# can register map
Vendor: Texas Instruments
Peripheral module from a debugger description file (folder sc4cc231e6pm).
Registers are 32-bit, read-write, no defined reset value unless marked. A register's access mark holds for its fields unless they carry their own. Offsets are as the file gives them; lines under a group give offsets from that group; [hi:lo] are bit positions; {n}, {i} and the like mark numbered series; 'fields as' and 'values as' point back to an identical list; <NAME> marks a mode.

## CAN0 — CAN register offsets
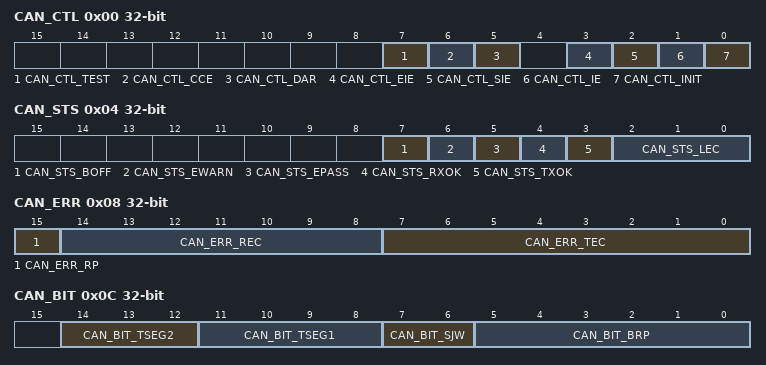
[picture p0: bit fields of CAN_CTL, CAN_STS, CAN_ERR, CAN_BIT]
0x00 CAN_CTL — CAN Control
  [7] CAN_CTL_TEST — Test Mode Enable
  [6] CAN_CTL_CCE — Configuration Change Enable
  [5] CAN_CTL_DAR — Disable Automatic-Retransmission
  [3] CAN_CTL_EIE — Error Interrupt Enable
  [2] CAN_CTL_SIE — Status Interrupt Enable
  [1] CAN_CTL_IE — CAN Interrupt Enable
  [0] CAN_CTL_INIT — Initialization
0x04 CAN_STS — CAN Status
  [7] CAN_STS_BOFF — Bus-Off Status
  [6] CAN_STS_EWARN — Warning Status
  [5] CAN_STS_EPASS — Error Passive
  [4] CAN_STS_RXOK — Received a Message Successfully
  [3] CAN_STS_TXOK — Transmitted a Message Successfully
  [2:0] CAN_STS_LEC — Last Error Code
    0=CAN_STS_LEC_NONE (No Error); 1=CAN_STS_LEC_STUFF (Stuff Error); 2=CAN_STS_LEC_FORM (Format Error); 3=CAN_STS_LEC_ACK (ACK Error); 4=CAN_STS_LEC_BIT1 (Bit 1 Error); 5=CAN_STS_LEC_BIT0 (Bit 0 Error); 6=CAN_STS_LEC_CRC (CRC Error); 7=CAN_STS_LEC_NOEVENT (No Event)
0x08 CAN_ERR ro — CAN Error Counter
  [15] CAN_ERR_RP — Received Error Passive
  [14:8] CAN_ERR_REC — Receive Error Counter
  [7:0] CAN_ERR_TEC — Transmit Error Counter
0x0C CAN_BIT — CAN Bit Timing
  [14:12] CAN_BIT_TSEG2 — Time Segment after Sample Point
  [11:8] CAN_BIT_TSEG1 — Time Segment Before Sample Point
  [7:6] CAN_BIT_SJW — (Re)Synchronization Jump Width
  [5:0] CAN_BIT_BRP — Baud Rate Prescaler
0x10 CAN_INT ro — CAN Interrupt
  [15:0] CAN_INT_INTID — Interrupt Identifier
    0=CAN_INT_INTID_NONE (No interrupt pending); 0x8000=CAN_INT_INTID_STATUS (Status Interrupt)
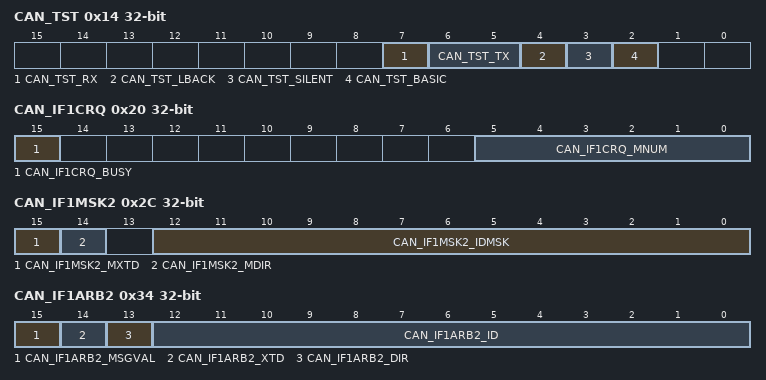
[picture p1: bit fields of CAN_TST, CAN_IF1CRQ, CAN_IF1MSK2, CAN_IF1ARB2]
0x14 CAN_TST — CAN Test
  [7] CAN_TST_RX — Receive Observation
  [6:5] CAN_TST_TX — Transmit Control
    0=CAN_TST_TX_CANCTL (CAN Module Control); 1=CAN_TST_TX_SAMPLE (Sample Point); 2=CAN_TST_TX_DOMINANT (Driven Low); 3=CAN_TST_TX_RECESSIVE (Driven High)
  [4] CAN_TST_LBACK — Loopback Mode
  [3] CAN_TST_SILENT — Silent Mode
  [2] CAN_TST_BASIC — Basic Mode
0x18 CAN_BRPE — CAN Baud Rate Prescaler Extension
  [3:0] CAN_BRPE_BRPE — Baud Rate Prescaler Extension
0x20 CAN_IF1CRQ — CAN IF1 Command Request
  [15] CAN_IF1CRQ_BUSY — Busy Flag
  [5:0] CAN_IF1CRQ_MNUM — Message Number
0x24 CAN_IF1CMSK — CAN IF1 Command Mask
  [7] CAN_IF1CMSK_WRNRD — Write, Not Read
  [6] CAN_IF1CMSK_MASK — Access Mask Bits
  [5] CAN_IF1CMSK_ARB — Access Arbitration Bits
  [4] CAN_IF1CMSK_CONTROL — Access Control Bits
  [3] CAN_IF1CMSK_CLRINTPND — Clear Interrupt Pending Bit
  [2] CAN_IF1CMSK_NEWDAT — Access New Data
  [2] CAN_IF1CMSK_TXRQST — Access Transmission Request
  [1] CAN_IF1CMSK_DATAA — Access Data Byte 0 to 3
  [0] CAN_IF1CMSK_DATAB — Access Data Byte 4 to 7
0x28 CAN_IF1MSK1 — CAN IF1 Mask 1
  [15:0] CAN_IF1MSK1_IDMSK — Identifier Mask
0x2C CAN_IF1MSK2 — CAN IF1 Mask 2
  [15] CAN_IF1MSK2_MXTD — Mask Extended Identifier
  [14] CAN_IF1MSK2_MDIR — Mask Message Direction
  [12:0] CAN_IF1MSK2_IDMSK — Identifier Mask
0x30 CAN_IF1ARB1 — CAN IF1 Arbitration 1
  [15:0] CAN_IF1ARB1_ID — Message Identifier
0x34 CAN_IF1ARB2 — CAN IF1 Arbitration 2
  [15] CAN_IF1ARB2_MSGVAL — Message Valid
  [14] CAN_IF1ARB2_XTD — Extended Identifier
  [13] CAN_IF1ARB2_DIR — Message Direction
  [12:0] CAN_IF1ARB2_ID — Message Identifier
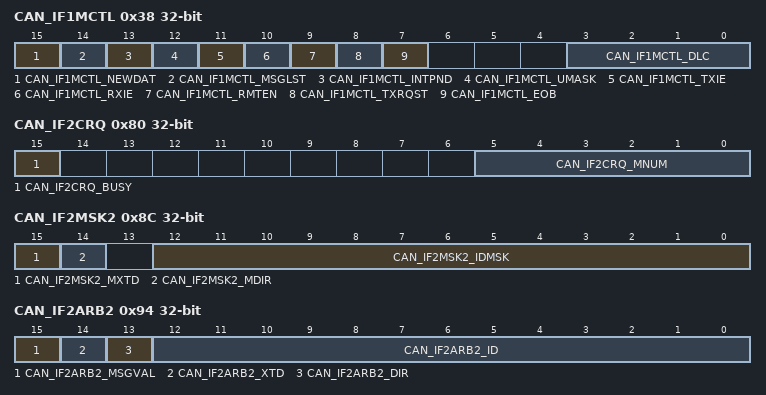
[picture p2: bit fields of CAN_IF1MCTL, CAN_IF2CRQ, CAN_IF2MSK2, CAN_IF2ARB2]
0x38 CAN_IF1MCTL — CAN IF1 Message Control
  [15] CAN_IF1MCTL_NEWDAT — New Data
  [14] CAN_IF1MCTL_MSGLST — Message Lost
  [13] CAN_IF1MCTL_INTPND — Interrupt Pending
  [12] CAN_IF1MCTL_UMASK — Use Acceptance Mask
  [11] CAN_IF1MCTL_TXIE — Transmit Interrupt Enable
  [10] CAN_IF1MCTL_RXIE — Receive Interrupt Enable
  [9] CAN_IF1MCTL_RMTEN — Remote Enable
  [8] CAN_IF1MCTL_TXRQST — Transmit Request
  [7] CAN_IF1MCTL_EOB — End of Buffer
  [3:0] CAN_IF1MCTL_DLC — Data Length Code
0x3C CAN_IF1DA1 — CAN IF1 Data A1
  [15:0] CAN_IF1DA1_DATA — Data
0x40 CAN_IF1DA2 — CAN IF1 Data A2
  [15:0] CAN_IF1DA2_DATA — Data
0x44 CAN_IF1DB1 — CAN IF1 Data B1
  [15:0] CAN_IF1DB1_DATA — Data
0x48 CAN_IF1DB2 — CAN IF1 Data B2
  [15:0] CAN_IF1DB2_DATA — Data
0x80 CAN_IF2CRQ — CAN IF2 Command Request
  [15] CAN_IF2CRQ_BUSY — Busy Flag
  [5:0] CAN_IF2CRQ_MNUM — Message Number
0x84 CAN_IF2CMSK — CAN IF2 Command Mask
  [7] CAN_IF2CMSK_WRNRD — Write, Not Read
  [6] CAN_IF2CMSK_MASK — Access Mask Bits
  [5] CAN_IF2CMSK_ARB — Access Arbitration Bits
  [4] CAN_IF2CMSK_CONTROL — Access Control Bits
  [3] CAN_IF2CMSK_CLRINTPND — Clear Interrupt Pending Bit
  [2] CAN_IF2CMSK_NEWDAT — Access New Data
  [2] CAN_IF2CMSK_TXRQST — Access Transmission Request
  [1] CAN_IF2CMSK_DATAA — Access Data Byte 0 to 3
  [0] CAN_IF2CMSK_DATAB — Access Data Byte 4 to 7
0x88 CAN_IF2MSK1 — CAN IF2 Mask 1
  [15:0] CAN_IF2MSK1_IDMSK — Identifier Mask
0x8C CAN_IF2MSK2 — CAN IF2 Mask 2
  [15] CAN_IF2MSK2_MXTD — Mask Extended Identifier
  [14] CAN_IF2MSK2_MDIR — Mask Message Direction
  [12:0] CAN_IF2MSK2_IDMSK — Identifier Mask
0x90 CAN_IF2ARB1 — CAN IF2 Arbitration 1
  [15:0] CAN_IF2ARB1_ID — Message Identifier
0x94 CAN_IF2ARB2 — CAN IF2 Arbitration 2
  [15] CAN_IF2ARB2_MSGVAL — Message Valid
  [14] CAN_IF2ARB2_XTD — Extended Identifier
  [13] CAN_IF2ARB2_DIR — Message Direction
  [12:0] CAN_IF2ARB2_ID — Message Identifier
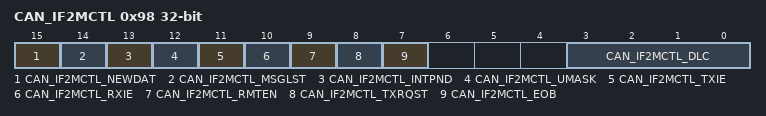
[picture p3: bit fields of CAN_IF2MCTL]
0x98 CAN_IF2MCTL — CAN IF2 Message Control
  [15] CAN_IF2MCTL_NEWDAT — New Data
  [14] CAN_IF2MCTL_MSGLST — Message Lost
  [13] CAN_IF2MCTL_INTPND — Interrupt Pending
  [12] CAN_IF2MCTL_UMASK — Use Acceptance Mask
  [11] CAN_IF2MCTL_TXIE — Transmit Interrupt Enable
  [10] CAN_IF2MCTL_RXIE — Receive Interrupt Enable
  [9] CAN_IF2MCTL_RMTEN — Remote Enable
  [8] CAN_IF2MCTL_TXRQST — Transmit Request
  [7] CAN_IF2MCTL_EOB — End of Buffer
  [3:0] CAN_IF2MCTL_DLC — Data Length Code
0x9C CAN_IF2DA1 — CAN IF2 Data A1
  [15:0] CAN_IF2DA1_DATA — Data
0xA0 CAN_IF2DA2 — CAN IF2 Data A2
  [15:0] CAN_IF2DA2_DATA — Data
0xA4 CAN_IF2DB1 — CAN IF2 Data B1
  [15:0] CAN_IF2DB1_DATA — Data
0xA8 CAN_IF2DB2 — CAN IF2 Data B2
  [15:0] CAN_IF2DB2_DATA — Data
0x100 CAN_TXRQ1 ro — CAN Transmission Request 1
  [15:0] CAN_TXRQ1_TXRQST — Transmission Request Bits
0x104 CAN_TXRQ2 ro — CAN Transmission Request 2
  [15:0] CAN_TXRQ2_TXRQST — Transmission Request Bits
0x120 CAN_NWDA1 ro — CAN New Data 1
  [15:0] CAN_NWDA1_NEWDAT — New Data Bits
0x124 CAN_NWDA2 ro — CAN New Data 2
  [15:0] CAN_NWDA2_NEWDAT — New Data Bits
0x140 CAN_MSG1INT ro — CAN Message 1 Interrupt Pending
  [15:0] CAN_MSG1INT_INTPND — Interrupt Pending Bits
0x144 CAN_MSG2INT ro — CAN Message 2 Interrupt Pending
  [15:0] CAN_MSG2INT_INTPND — Interrupt Pending Bits
0x160 CAN_MSG1VAL ro — CAN Message 1 Valid
  [15:0] CAN_MSG1VAL_MSGVAL — Message Valid Bits
0x164 CAN_MSG2VAL ro — CAN Message 2 Valid
  [15:0] CAN_MSG2VAL_MSGVAL — Message Valid Bits
